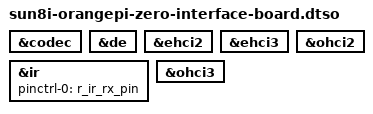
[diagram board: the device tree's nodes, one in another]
// SPDX-License-Identifier: (GPL-2.0-or-later OR X11)
/*
 * Copyright (C) 2025 J. Neuschäfer <j.ne@posteo.net>
 *
 * Devicetree overlay for the Orange Pi Zero Interface board (OP0014).
 *
 *   https://orangepi.com/index.php?route=product/product&product_id=871
 *
 * This overlay applies to the following base files:
 *
 * - arch/arm/boot/dts/allwinner/sun8i-h2-plus-orangepi-zero.dts
 * - arch/arm/boot/dts/allwinner/sun8i-h3-orangepi-zero-plus2.dts
 */

/dts-v1/;
/plugin/;

&codec {
	status = "okay";
};

&de {
	status = "okay";
};

&ehci2 {
	status = "okay";
};

&ehci3 {
	status = "okay";
};

&ir {
	pinctrl-names = "default";
	pinctrl-0 = <&r_ir_rx_pin>;
	status = "okay";
};

&ohci2 {
	status = "okay";
};

&ohci3 {
	status = "okay";
};
